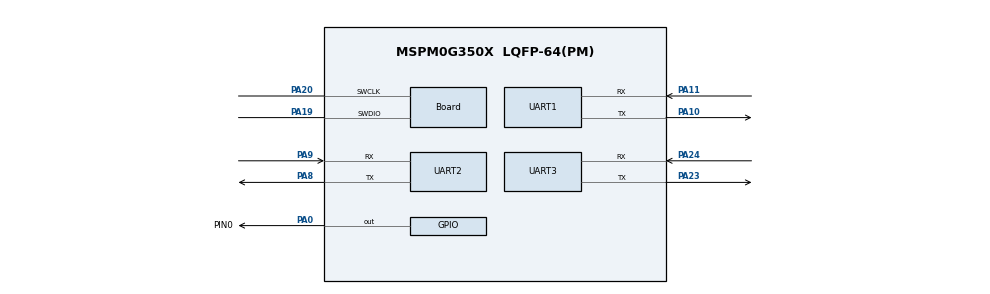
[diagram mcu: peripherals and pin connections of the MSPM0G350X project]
/**
 * @cliArgs --device "MSPM0G350X" --package "LQFP-64(PM)" --part "Default" --product "mspm0_sdk@2.00.01.00"
 * @versions {"tool":"1.20.0+3587"}
 */

/**
 * Import the modules used in this configuration.
 */
const GPIO          = scripting.addModule("/ti/driverlib/GPIO", {}, false);
const GPIO1         = GPIO.addInstance();
const GPIO2         = GPIO.addInstance();
const SYSCTL        = scripting.addModule("/ti/driverlib/SYSCTL");
const SYSTICK       = scripting.addModule("/ti/driverlib/SYSTICK");
const TIMER         = scripting.addModule("/ti/driverlib/TIMER", {}, false);
const TIMER1        = TIMER.addInstance();
const UART          = scripting.addModule("/ti/driverlib/UART", {}, false);
const UART1         = UART.addInstance();
const UART2         = UART.addInstance();
const UART3         = UART.addInstance();
const ProjectConfig = scripting.addModule("/ti/project_config/ProjectConfig");

/**
 * Write custom configuration values to the imported modules.
 */
const gate7  = system.clockTree["MFCLKGATE"];
gate7.enable = true;

GPIO1.$name                              = "LED";
GPIO1.port                               = "PORTA";
GPIO1.associatedPins[0].internalResistor = "PULL_UP";
GPIO1.associatedPins[0].$name            = "PIN0";
GPIO1.associatedPins[0].assignedPin      = "0";
GPIO1.associatedPins[0].pin.$assign      = "PA0";

const Board                       = scripting.addModule("/ti/driverlib/Board", {}, false);
Board.peripheral.$assign          = "DEBUGSS";
Board.peripheral.swclkPin.$assign = "PA20";
Board.peripheral.swdioPin.$assign = "PA19";

GPIO2.$name                          = "OLED";
GPIO2.port                           = "PORTA";
GPIO2.associatedPins.create(2);
GPIO2.associatedPins[0].$name        = "SCL";
GPIO2.associatedPins[0].initialValue = "SET";
GPIO2.associatedPins[0].assignedPin  = "12";
GPIO2.associatedPins[1].initialValue = "SET";
GPIO2.associatedPins[1].$name        = "SDA";
GPIO2.associatedPins[1].assignedPin  = "14";

SYSCTL.forceDefaultClkConfig = true;
SYSCTL.clockTreeEn           = true;

SYSTICK.periodEnable      = true;
SYSTICK.interruptPriority = "0";
SYSTICK.systickEnable     = true;
SYSTICK.period            = 32;

TIMER1.$name              = "TIMER_0";
TIMER1.timerClkDiv        = 8;
TIMER1.timerPeriod        = "100ms";
TIMER1.timerStartTimer    = true;
TIMER1.interrupts         = ["ZERO"];
TIMER1.timerClkPrescale   = 100;
TIMER1.timerMode          = "PERIODIC";
TIMER1.peripheral.$assign = "TIMG0";

UART1.$name                    = "UART_0";
UART1.uartClkSrc               = "MFCLK";
UART1.enabledInterrupts        = ["RX"];
UART1.targetBaudRate           = 115200;
UART1.peripheral.$assign       = "UART0";
UART1.peripheral.rxPin.$assign = "PA11";
UART1.peripheral.txPin.$assign = "PA10";
UART1.txPinConfig.$name        = "ti_driverlib_gpio_GPIOPinGeneric0";
UART1.rxPinConfig.$name        = "ti_driverlib_gpio_GPIOPinGeneric1";

UART2.$name                    = "UART_1";
UART2.uartClkSrc               = "MFCLK";
UART2.enabledInterrupts        = ["RX"];
UART2.targetBaudRate           = 115200;
UART2.peripheral.$assign       = "UART1";
UART2.peripheral.rxPin.$assign = "PA9";
UART2.peripheral.txPin.$assign = "PA8";
UART2.txPinConfig.$name        = "ti_driverlib_gpio_GPIOPinGeneric2";
UART2.rxPinConfig.$name        = "ti_driverlib_gpio_GPIOPinGeneric3";

UART3.$name                    = "UART_2";
UART3.uartClkSrc               = "MFCLK";
UART3.enabledInterrupts        = ["RX"];
UART3.targetBaudRate           = 115200;
UART3.peripheral.$assign       = "UART2";
UART3.peripheral.rxPin.$assign = "PA24";
UART3.peripheral.txPin.$assign = "PA23";
UART3.txPinConfig.$name        = "ti_driverlib_gpio_GPIOPinGeneric4";
UART3.rxPinConfig.$name        = "ti_driverlib_gpio_GPIOPinGeneric5";

ProjectConfig.switchCondition = true;
scripting.suppress("Migrating requires going through the Switch Board or Device menu in the Device View section\\.", ProjectConfig, "deviceSpin");

/**
 * Pinmux solution for unlocked pins/peripherals. This ensures that minor changes to the automatic solver in a future
 * version of the tool will not impact the pinmux you originally saw.  These lines can be completely deleted in order to
 * re-solve from scratch.
 */
GPIO2.associatedPins[0].pin.$suggestSolution = "PA12";
GPIO2.associatedPins[1].pin.$suggestSolution = "PA14";
